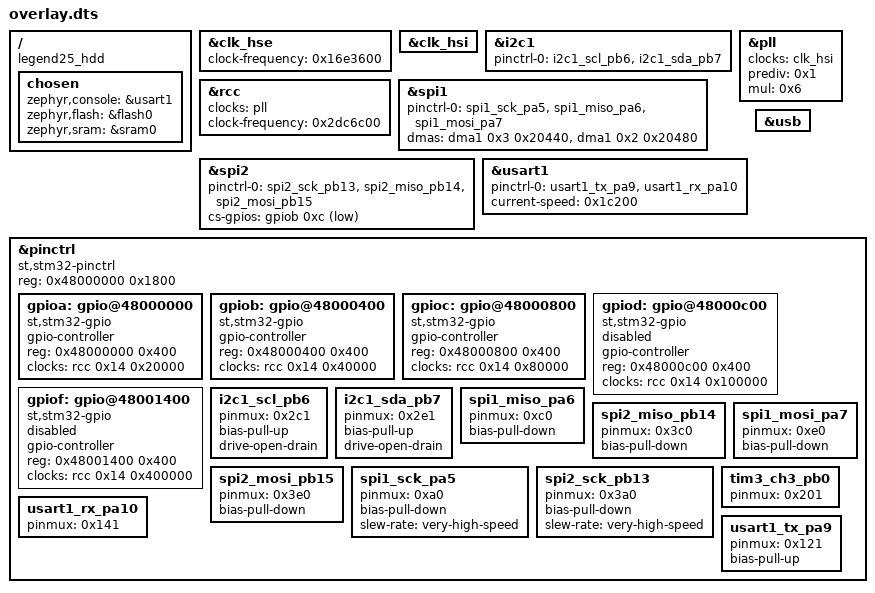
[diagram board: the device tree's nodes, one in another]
/ {
	compatible = "legend25_hdd", "seagate,legend25_hdd";
	chosen {
		zephyr,console = &usart1;
		zephyr,flash = &flash0;
		zephyr,sram = &sram0;
	};
};
&clk_hse{
	status = "okay";
	clock-frequency = < 0x16e3600 >;
};
&clk_hsi{
	status = "okay";
};
&i2c1{
	status = "okay";
	pinctrl-0 = < &i2c1_scl_pb6 &i2c1_sda_pb7 >;
	pinctrl-names = "default";
};
&pll{
	status = "okay";
	clocks = < &clk_hsi >;
	prediv = < 0x1 >;
	mul = < 0x6 >;
};
&rcc{
	clocks = < &pll >;
	clock-frequency = < 0x2dc6c00 >;
};
&spi1{
	status = "okay";
	pinctrl-0 = < &spi1_sck_pa5 &spi1_miso_pa6 &spi1_mosi_pa7 >;
	pinctrl-names = "default";
	dmas = < &dma1 0x3 0x20440 >, < &dma1 0x2 0x20480 >;
	dma-names = "tx", "rx";
};
&spi2{
	status = "okay";
	pinctrl-0 = < &spi2_sck_pb13 &spi2_miso_pb14 &spi2_mosi_pb15 >;
	pinctrl-names = "default";
	cs-gpios = < &gpiob 0xc 0x1 >;
};
&usart1{
	status = "okay";
	pinctrl-0 = < &usart1_tx_pa9 &usart1_rx_pa10 >;
	pinctrl-names = "default";
	current-speed = < 0x1c200 >;
};
&usb{
	status = "okay";
};
&pinctrl{
	compatible = "st,stm32-pinctrl";
	#address-cells = < 0x1 >;
	#size-cells = < 0x1 >;
	reg = < 0x48000000 0x1800 >;
	gpioa: gpio@48000000 {
		compatible = "st,stm32-gpio";
		gpio-controller;
		#gpio-cells = < 0x2 >;
		reg = < 0x48000000 0x400 >;
		clocks = < &rcc 0x14 0x20000 >;
	};
	gpiob: gpio@48000400 {
		compatible = "st,stm32-gpio";
		gpio-controller;
		#gpio-cells = < 0x2 >;
		reg = < 0x48000400 0x400 >;
		clocks = < &rcc 0x14 0x40000 >;
	};
	gpioc: gpio@48000800 {
		compatible = "st,stm32-gpio";
		gpio-controller;
		#gpio-cells = < 0x2 >;
		reg = < 0x48000800 0x400 >;
		clocks = < &rcc 0x14 0x80000 >;
	};
	gpiod: gpio@48000c00 {
		compatible = "st,stm32-gpio";
		gpio-controller;
		#gpio-cells = < 0x2 >;
		reg = < 0x48000c00 0x400 >;
		clocks = < &rcc 0x14 0x100000 >;
		status = "disabled";
	};
	gpiof: gpio@48001400 {
		compatible = "st,stm32-gpio";
		gpio-controller;
		#gpio-cells = < 0x2 >;
		reg = < 0x48001400 0x400 >;
		clocks = < &rcc 0x14 0x400000 >;
		status = "disabled";
	};
	i2c1_scl_pb6: i2c1_scl_pb6 {
		pinmux = < 0x2c1 >;
		bias-pull-up;
		drive-open-drain;
	};
	i2c1_sda_pb7: i2c1_sda_pb7 {
		pinmux = < 0x2e1 >;
		bias-pull-up;
		drive-open-drain;
	};
	spi1_miso_pa6: spi1_miso_pa6 {
		pinmux = < 0xc0 >;
		bias-pull-down;
	};
	spi2_miso_pb14: spi2_miso_pb14 {
		pinmux = < 0x3c0 >;
		bias-pull-down;
	};
	spi1_mosi_pa7: spi1_mosi_pa7 {
		pinmux = < 0xe0 >;
		bias-pull-down;
	};
	spi2_mosi_pb15: spi2_mosi_pb15 {
		pinmux = < 0x3e0 >;
		bias-pull-down;
	};
	spi1_sck_pa5: spi1_sck_pa5 {
		pinmux = < 0xa0 >;
		bias-pull-down;
		slew-rate = "very-high-speed";
	};
	spi2_sck_pb13: spi2_sck_pb13 {
		pinmux = < 0x3a0 >;
		bias-pull-down;
		slew-rate = "very-high-speed";
	};
	tim3_ch3_pb0: tim3_ch3_pb0 {
		pinmux = < 0x201 >;
	};
	usart1_rx_pa10: usart1_rx_pa10 {
		pinmux = < 0x141 >;
	};
	usart1_tx_pa9: usart1_tx_pa9 {
		pinmux = < 0x121 >;
		bias-pull-up;
	};
};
